# APM32F051 register map
File version: 1.0
Registers are 32-bit, read-write, reset 0x0 unless marked. A register's access mark holds for its fields unless they carry their own. Offsets are from the block's base; [hi:lo] are bit positions.

## CEC — HDMI-CEC registers
Base 0x40007800
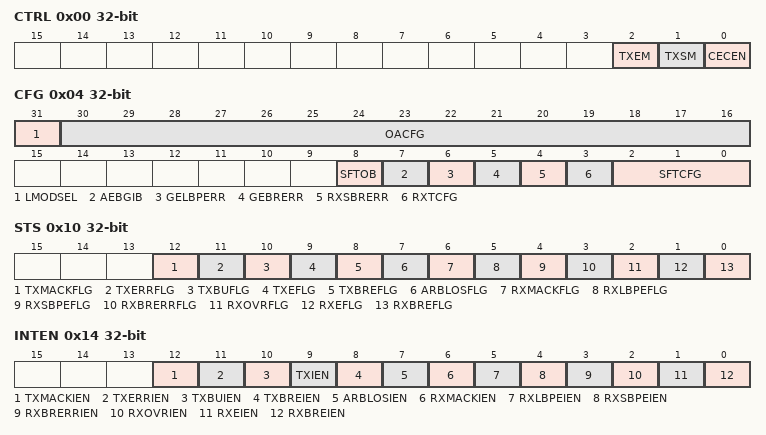
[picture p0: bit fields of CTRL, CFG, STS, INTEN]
0x00 CTRL — CEC control register
  [2] TXEM — Tx End Of Message
  [1] TXSM — Tx Start Of Message
  [0] CECEN — CEC Enable
0x04 CFG — CEC configuration register
  [31] LMODSEL — Listen mode
  [30:16] OACFG — Own addresses configuration
  [8] SFTOB — SFT Option Bit
  [7] AEBGIB — Avoid Error-Bit Generation in Broadcast
  [6] GELBPERR — Generate Error-Bit on Long Bit Period Error
  [5] GEBRERR — Generate Error-Bit on Bit Rising Error
  [4] RXSBRERR — Rx-Stop on Bit Rising Error
  [3] RXTCFG — Rx-Tolerance
  [2:0] SFTCFG — Signal Free Time
0x08 TXDATA wo — CEC Tx data register
  [7:0] TXDATA
0x0C RXDATA ro — CEC Rx data register
  [7:0] RXDATA
0x10 STS — CEC Interrupt and Status Register
  [12] TXMACKFLG — Tx-Missing Acknowledge Error
  [11] TXERRFLG — Tx-Error
  [10] TXBUFLG — Tx-Buffer Underrun
  [9] TXEFLG — End of Transmission
  [8] TXBREFLG — Tx-Byte Request
  [7] ARBLOSFLG — Arbitration Lost
  [6] RXMACKFLG — Rx-Missing Acknowledge
  [5] RXLBPEFLG — Rx-Long Bit Period Error
  [4] RXSBPEFLG — Rx-Short Bit Period Error
  [3] RXBRERRFLG — Rx-Bit Rising Error
  [2] RXOVRFLG — Rx-Overrun
  [1] RXEFLG — End Of Reception
  [0] RXBREFLG — Rx-Byte Received
0x14 INTEN — CEC interrupt enable register
  [12] TXMACKIEN — Tx-Missing Acknowledge Error Interrupt Enable
  [11] TXERRIEN — Tx-Error Interrupt Enable
  [10] TXBUIEN — Tx-Underrun Interrupt Enable
  [9] TXIEN — Tx-End Of Message Interrupt Enable
  [8] TXBREIEN — Tx-Byte Request Interrupt Enable
  [7] ARBLOSIEN — Arbitration Lost Interrupt Enable
  [6] RXMACKIEN — Rx-Missing Acknowledge Error Interrupt Enable
  [5] RXLBPEIEN — Long Bit Period Error Interrupt Enable
  [4] RXSBPEIEN — Short Bit Period Error Interrupt Enable
  [3] RXBRERRIEN — Bit Rising Error Interrupt Enable
  [2] RXOVRIEN — Rx-Buffer Overrun Interrupt Enable
  [1] RXEIEN — End Of Reception Interrupt Enable
  [0] RXBREIEN — Rx-Byte Received Interrupt Enable

## TMR6 — Basic-timers
Base 0x40001000
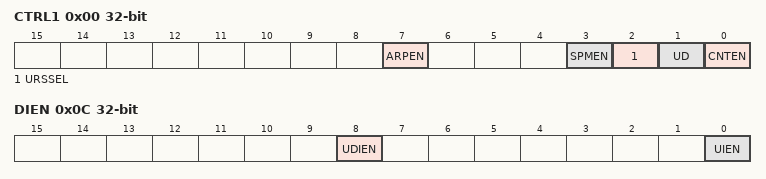
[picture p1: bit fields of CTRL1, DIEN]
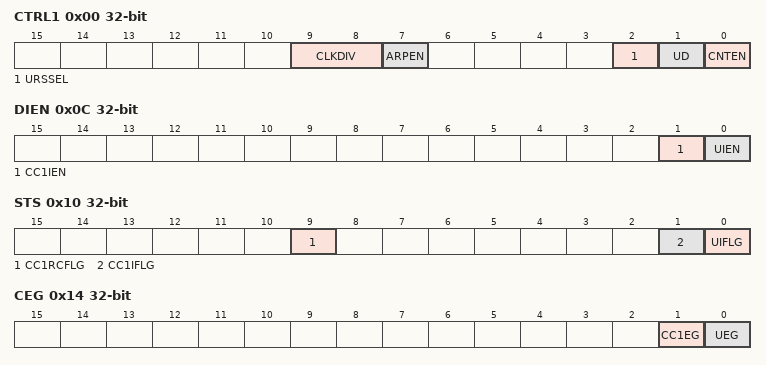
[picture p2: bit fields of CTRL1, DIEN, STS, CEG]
0x00 CTRL1 — control register 1
  [7] ARPEN — Auto-reload preload enable
  [3] SPMEN — One-pulse mode
  [2] URSSEL — Update request source
  [1] UD — Update disable
  [0] CNTEN — Counter enable
0x0C DIEN — DMA/Interrupt enable register
  [8] UDIEN — Update DMA request enable
  [0] UIEN — Update interrupt enable
0x10 STS — status register
  [0] UIFLG — Update interrupt flag
0x14 CEG wo — event generation register
  [0] UEG — Update generation
0x24 CNT — counter
  [15:0] CNT — Low counter value
0x28 PSC — prescaler
  [15:0] PSC — Prescaler value
0x2C AUTORLD reset 0xFFFF — auto-reload register
  [15:0] AUTORLD — Low Auto-reload value

## TMR14 — General-purpose-timers
Base 0x40002000
0x00 CTRL1 — control register 1
  [9:8] CLKDIV — Clock division
  [7] ARPEN — Auto-reload preload enable
  [2] URSSEL — Update request source
  [1] UD — Update disable
  [0] CNTEN — Counter enable
0x0C DIEN — DMA/Interrupt enable register
  [1] CC1IEN — Capture/Compare 1 interrupt enable
  [0] UIEN — Update interrupt enable
0x10 STS — status register
  [9] CC1RCFLG — Capture/Compare 1 overcapture flag
  [1] CC1IFLG — Capture/compare 1 interrupt flag
  [0] UIFLG — Update interrupt flag
0x14 CEG wo — event generation register
  [1] CC1EG — Capture/compare 1 generation
  [0] UEG — Update generation
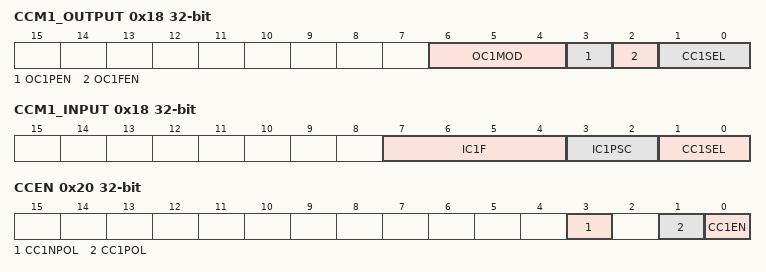
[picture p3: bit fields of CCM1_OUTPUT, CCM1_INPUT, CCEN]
0x18 CCM1_OUTPUT — capture/compare mode register (output mode)
  [6:4] OC1MOD — Output Compare 1 mode
  [3] OC1PEN — Output Compare 1 preload enable
  [2] OC1FEN — Output Compare 1 fast enable
  [1:0] CC1SEL — Capture/Compare 1 selection
0x18 CCM1_INPUT (alternate view of CCM1_OUTPUT) — capture/compare mode register 1 (input mode)
  [7:4] IC1F — Input capture 1 filter
  [3:2] IC1PSC — Input capture 1 prescaler
  [1:0] CC1SEL — Capture/Compare 1 selection
0x20 CCEN — capture/compare enable register
  [3] CC1NPOL — Capture/Compare 1 output Polarity
  [1] CC1POL — Capture/Compare 1 output Polarity
  [0] CC1EN — Capture/Compare 1 output enable
0x24 CNT — counter
  [15:0] CNT — counter value
0x28 PSC — prescaler
  [15:0] PSC — Prescaler value
0x2C AUTORLD reset 0xFFFF — auto-reload register
  [15:0] AUTORLD — Auto-reload value
0x34 CC1 — capture/compare register 1
  [15:0] CC1 — Capture/Compare 1 value
0x50 OPT — option register
  [1:0] RMPSEL — Timer input 1 remap

## TMR15 — General-purpose-timers
Base 0x40014000
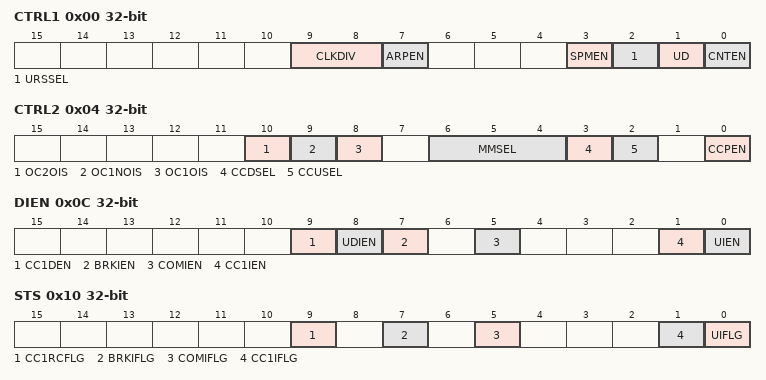
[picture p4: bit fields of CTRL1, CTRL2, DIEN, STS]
0x00 CTRL1 — control register 1
  [9:8] CLKDIV — Clock division
  [7] ARPEN — Auto-reload preload enable
  [3] SPMEN — One-pulse mode
  [2] URSSEL — Update request source
  [1] UD — Update disable
  [0] CNTEN — Counter enable
0x04 CTRL2 — control register 2
  [10] OC2OIS — Output Idle state 2
  [9] OC1NOIS — Output Idle state 1
  [8] OC1OIS — Output Idle state 1
  [6:4] MMSEL — Master Mode Signal Select
  [3] CCDSEL — Capture/compare DMA selection
  [2] CCUSEL — Capture/compare control update selection
  [0] CCPEN — Capture/compare preloaded control
0x0C DIEN — DMA/Interrupt enable register
  [9] CC1DEN — Capture/Compare 1 DMA request enable
  [8] UDIEN — Update DMA request enable
  [7] BRKIEN — Break interrupt enable
  [5] COMIEN — COM interrupt enable
  [1] CC1IEN — Capture/Compare 1 interrupt enable
  [0] UIEN — Update interrupt enable
0x10 STS — status register
  [9] CC1RCFLG — Capture/Compare 1 overcapture flag
  [7] BRKIFLG — Break interrupt flag
  [5] COMIFLG — COM interrupt flag
  [1] CC1IFLG — Capture/compare 1 interrupt flag
  [0] UIFLG — Update interrupt flag
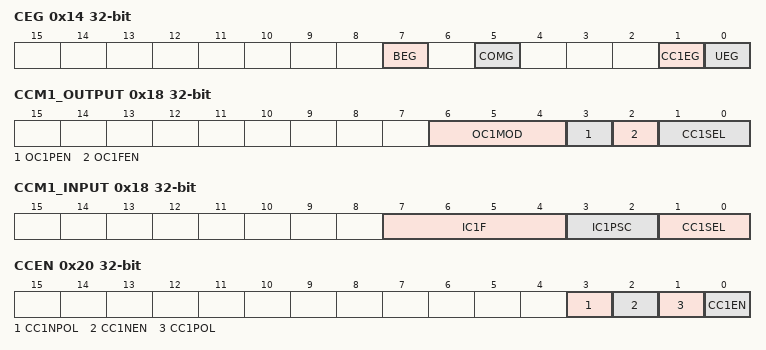
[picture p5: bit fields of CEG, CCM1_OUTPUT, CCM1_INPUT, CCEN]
0x14 CEG wo — event generation register
  [7] BEG — Break generation
  [5] COMG — Capture/Compare control update generation
  [1] CC1EG — Capture/compare 1 generation
  [0] UEG — Update generation
0x18 CCM1_OUTPUT — capture/compare mode register (output mode)
  [6:4] OC1MOD — Output Compare 1 mode
  [3] OC1PEN — Output Compare 1 preload enable
  [2] OC1FEN — Output Compare 1 fast enable
  [1:0] CC1SEL — Capture/Compare 1 selection
0x18 CCM1_INPUT (alternate view of CCM1_OUTPUT) — capture/compare mode register 1 (input mode)
  [7:4] IC1F — Input capture 1 filter
  [3:2] IC1PSC — Input capture 1 prescaler
  [1:0] CC1SEL — Capture/Compare 1 selection
0x20 CCEN — capture/compare enable register
  [3] CC1NPOL — Capture/Compare 1 output Polarity
  [2] CC1NEN — Capture/Compare 1 complementary output enable
  [1] CC1POL — Capture/Compare 1 output Polarity
  [0] CC1EN — Capture/Compare 1 output enable
0x24 CNT — counter
  [15:0] CNT — counter value
0x28 PSC — prescaler
  [15:0] PSC — Prescaler value
0x2C AUTORLD reset 0xFFFF — auto-reload register
  [15:0] AUTORLD — Auto-reload value
0x30 REPCNT — repetition counter register
  [7:0] REPCNT — Repetition counter value
0x34 CC1 — capture/compare register 1
  [15:0] CC1 — Capture/Compare 1 value
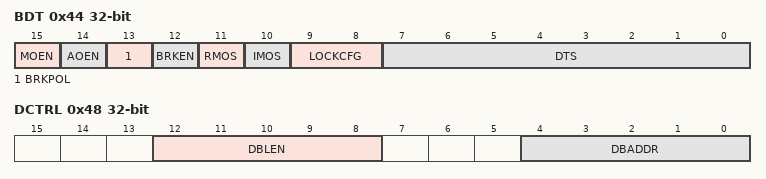
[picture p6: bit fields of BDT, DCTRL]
0x44 BDT — break and dead-time register
  [15] MOEN — Main output enable
  [14] AOEN — Automatic output enable
  [13] BRKPOL — Break polarity
  [12] BRKEN — Break enable
  [11] RMOS — Off-state selection for Run mode
  [10] IMOS — Off-state selection for Idle mode
  [9:8] LOCKCFG — Lock configuration
  [7:0] DTS — Dead-time generator setup
0x48 DCTRL — DMA control register
  [12:8] DBLEN — DMA burst length
  [4:0] DBADDR — DMA base address
0x4C DMADDR — DMA address for full transfer
  [15:0] DMADDR — DMA register for burst accesses

## TMR16 — General-purpose-timers
Base 0x40014400
Same registers: TMR17 0x40014800
Registers as TMR15; these are added or differ:
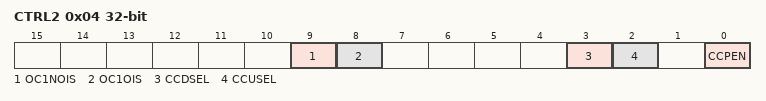
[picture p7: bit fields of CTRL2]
0x04 CTRL2 — control register 2
  [9] OC1NOIS — Output Idle state 1
  [8] OC1OIS — Output Idle state 1
  [3] CCDSEL — Capture/compare DMA selection
  [2] CCUSEL — Capture/compare control update selection
  [0] CCPEN — Capture/compare preloaded control
